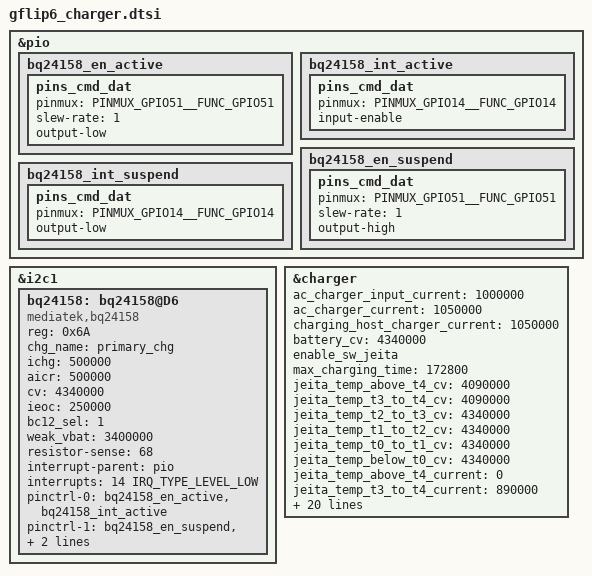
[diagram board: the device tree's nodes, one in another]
&pio {
	bq24158_en_active:bq24158_en_active {
		pins_cmd_dat {
			pinmux = <PINMUX_GPIO51__FUNC_GPIO51>;
			slew-rate = <1>;
			output-low;
		};
	};
	bq24158_int_active: bq24158_int_active {
		pins_cmd_dat {
			pinmux = <PINMUX_GPIO14__FUNC_GPIO14>;
			input-enable;
		};
	};
	bq24158_en_suspend:bq24158_en_suspend {
		pins_cmd_dat {
			pinmux = <PINMUX_GPIO51__FUNC_GPIO51>;
			slew-rate = <1>;
			output-high;
		};
	};
	bq24158_int_suspend: bq24158_int_suspend {
		pins_cmd_dat {
			pinmux = <PINMUX_GPIO14__FUNC_GPIO14>;
			output-low;
		};
	};
};

&i2c1 {
	status = "okay";
	bq24158:bq24158@D6{
		compatible = "mediatek,bq24158";
		reg = <0x6A>;
		chg_name = "primary_chg";
		ichg = <500000>;		/* uA */
		aicr = <500000>;		/* uA */
		cv = <4340000>;			/* uV */
		ieoc = <250000>;		/* uA */
		bc12_sel = <1>;
		weak_vbat = <3400000>;
		resistor-sense = <68>;
		interrupt-parent = <&pio>;
		interrupts = <14 IRQ_TYPE_LEVEL_LOW>;
		interrupt-names = "bq24158_chg_stat_irq";
		pinctrl-names = "bq24158_active", "bq24158_suspend";
		pinctrl-0 = <&bq24158_en_active &bq24158_int_active>;
		pinctrl-1 = <&bq24158_en_suspend &bq24158_int_suspend>;
		enable_gflip6_series; /*except gflip6gc and charger will be use eta6937*/
		status = "okay";
	};
};

&charger {
	/delete-property/enable_pe_plus;
	/delete-property/enable_pe_2;
	/delete-property/enable_pe_3;
	ac_charger_input_current = <1000000>;
	ac_charger_current = <1050000>;
	charging_host_charger_current = <1050000>;
	battery_cv = <4340000>;
	enable_sw_jeita;
	max_charging_time = <172800>; /* 2 days */
	/* sw jeita */
	jeita_temp_above_t4_cv = <4090000>;
	jeita_temp_t3_to_t4_cv = <4090000>;
	jeita_temp_t2_to_t3_cv = <4340000>;
	jeita_temp_t1_to_t2_cv = <4340000>;
	jeita_temp_t0_to_t1_cv = <4340000>;
	jeita_temp_below_t0_cv = <4340000>;
	jeita_temp_above_t4_current = <0>;
	jeita_temp_t3_to_t4_current = <890000>;
	jeita_temp_t2_to_t3_current = <1050000>;
	jeita_temp_t1_to_t2_current = <550000>;
	jeita_temp_t0_to_t1_current = <550000>;
	jeita_temp_below_t0_current = <0>;

	temp_t4_thres = <53>;
	temp_t4_thres_minus_x_degree = <51>;
	temp_t3_thres = <42>;
	temp_t3_thres_minus_x_degree = <43>;
	temp_t2_thres = <11>;
	temp_t2_thres_plus_x_degree = <10>;
	temp_t1_thres = <6>;
	temp_t1_thres_plus_x_degree = <5>;
	temp_t0_thres = <2>;
	temp_t0_thres_plus_x_degree = <1>;
	temp_neg_10_thres = <2>;

	enable_min_charge_temp;
	min_charge_temp = <1>;
	min_charge_temp_plus_x_degree = <2>;
	max_charge_temp = <53>;
	max_charge_temp_minus_x_degree = <51>;
};
